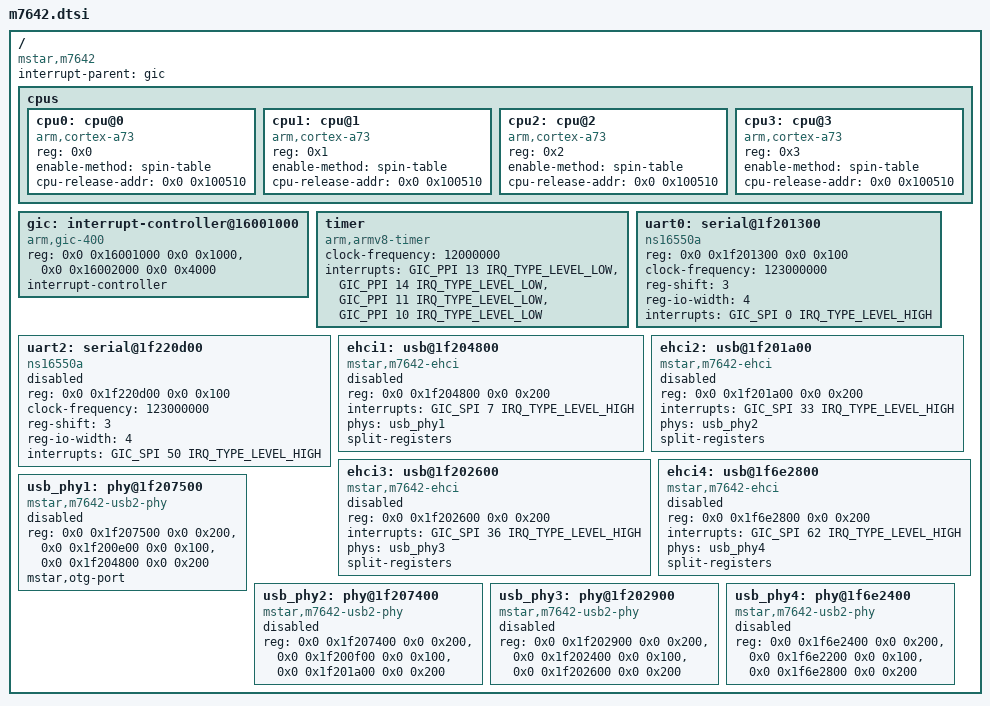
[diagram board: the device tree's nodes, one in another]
// SPDX-License-Identifier: (GPL-2.0+ OR MIT)
/*
 * MStar m7642 (marketed by MediaTek as MT9652)
 *
 * Only the blocks that mainline Linux can drive are described.  Everything
 * else on this SoC is behind closed HAL code with no documented register
 * map, so inventing nodes for it would only produce empty drivers.  See
 * Documentation/mstar/m7642/ for what is known about each block.
 *
 * Naming: the vendor DT roots at "arm,m7642"; upstream wants the real
 * vendor prefix, which is registered as "mstar," in vendor-prefixes.yaml.
 */

#include <dt-bindings/interrupt-controller/arm-gic.h>

/ {
	compatible = "mstar,m7642";
	#address-cells = <2>;
	#size-cells = <2>;
	interrupt-parent = <&gic>;

	cpus {
		#address-cells = <1>;
		#size-cells = <0>;

		cpu0: cpu@0 {
			device_type = "cpu";
			compatible = "arm,cortex-a73";
			reg = <0x0>;
			enable-method = "spin-table";
			cpu-release-addr = <0x0 0x100510>;
		};

		cpu1: cpu@1 {
			device_type = "cpu";
			compatible = "arm,cortex-a73";
			reg = <0x1>;
			enable-method = "spin-table";
			cpu-release-addr = <0x0 0x100510>;
		};

		cpu2: cpu@2 {
			device_type = "cpu";
			compatible = "arm,cortex-a73";
			reg = <0x2>;
			enable-method = "spin-table";
			cpu-release-addr = <0x0 0x100510>;
		};

		cpu3: cpu@3 {
			device_type = "cpu";
			compatible = "arm,cortex-a73";
			reg = <0x3>;
			enable-method = "spin-table";
			cpu-release-addr = <0x0 0x100510>;
		};
	};

	/*
	 * The firmware has no PSCI.  The vendor release protocol is a three
	 * word mailbox at pm_base + (cpu-release-addr * 2) followed by an ack
	 * handshake, which does not match mainline spin-table.  Booting with
	 * maxcpus=1 is the only thing that works until a matching
	 * cpu_operations implementation exists (see smp.md).
	 */

	gic: interrupt-controller@16001000 {
		compatible = "arm,gic-400";
		reg = <0x0 0x16001000 0x0 0x1000>,	/* GICD */
		      <0x0 0x16002000 0x0 0x4000>;	/* GICC */
		interrupt-controller;
		#interrupt-cells = <3>;
	};

	/*
	 * No timer node in the vendor DT -- its board code registers the
	 * architected timer by hand.  The PPI assignments below are the
	 * architectural ones and need no knowledge of the SoC.
	 *
	 * clock-frequency is 12 MHz, read out of the vendor DT (0xb71b00).
	 * It has to be spelled out: mboot does not program CNTFRQ_EL0, and
	 * without a frequency the driver cannot register a clock event and
	 * the kernel panics before it can print anything.
	 */
	timer {
		compatible = "arm,armv8-timer";
		clock-frequency = <12000000>;
		interrupts = <GIC_PPI 13 IRQ_TYPE_LEVEL_LOW>,
			     <GIC_PPI 14 IRQ_TYPE_LEVEL_LOW>,
			     <GIC_PPI 11 IRQ_TYPE_LEVEL_LOW>,
			     <GIC_PPI 10 IRQ_TYPE_LEVEL_LOW>;
	};

	/*
	 * 8250 with 8-byte register stride: register N lives at byte
	 * offset N * 8.  The vendor patch redefines the register offsets to
	 * 0x00/0x02/0x04.. and then shifts by two, which is the same thing
	 * as reg-shift = <3> with 32-bit access.  123 MHz on real silicon.
	 */
	uart0: serial@1f201300 {
		compatible = "ns16550a";
		reg = <0x0 0x1f201300 0x0 0x100>;
		clock-frequency = <123000000>;
		reg-shift = <3>;
		reg-io-width = <4>;
		interrupts = <GIC_SPI 0 IRQ_TYPE_LEVEL_HIGH>;
	};

	/*
	 * mboot prints on UART2 (its env says console=ttyS2,115200n8) while
	 * the vendor kernel uses UART0.  Enable this one as well when a serial
	 * cable is attached, otherwise the bootloader stage looks silent.
	 * Kept disabled by default: the input clock has not been measured yet.
	 */
	uart2: serial@1f220d00 {
		compatible = "ns16550a";
		reg = <0x0 0x1f220d00 0x0 0x100>;
		clock-frequency = <123000000>;
		reg-shift = <3>;
		reg-io-width = <4>;
		interrupts = <GIC_SPI 50 IRQ_TYPE_LEVEL_HIGH>;
		status = "disabled";
	};

	/*
	 * Four EHCI controllers, all with 16-bit registers (see
	 * "split-registers" below).  The addresses are the vendor "ehc" base
	 * inside the USB block at 0x1f200000, the interrupts are the vendor
	 * virqs from /proc/interrupts minus 32, and the bus number column is
	 * what the hardware reports at runtime:
	 *
	 *   ehci1  0x4800  virq 39  -> SPI  7  bus usb2
	 *   ehci2  0x1a00  virq 65  -> SPI 33  bus usb1
	 *   ehci3  0x2600  virq 68  -> SPI 36  bus usb3  (MT7663 wifi/BT)
	 *   ehci4  0x4e2800 virq 94 -> SPI 62  bus usb4
	 *
	 * Disabled on purpose: the UTMI PHY sequence is not in the kernel
	 * yet, and the port never leaves reset without it.
	 */
	ehci1: usb@1f204800 {
		compatible = "mstar,m7642-ehci", "generic-ehci";
		reg = <0x0 0x1f204800 0x0 0x200>;
		interrupts = <GIC_SPI 7 IRQ_TYPE_LEVEL_HIGH>;
		phys = <&usb_phy1>;
		split-registers;
		status = "disabled";
	};

	ehci2: usb@1f201a00 {
		compatible = "mstar,m7642-ehci", "generic-ehci";
		reg = <0x0 0x1f201a00 0x0 0x200>;
		interrupts = <GIC_SPI 33 IRQ_TYPE_LEVEL_HIGH>;
		phys = <&usb_phy2>;
		split-registers;
		status = "disabled";
	};

	ehci3: usb@1f202600 {
		compatible = "mstar,m7642-ehci", "generic-ehci";
		reg = <0x0 0x1f202600 0x0 0x200>;
		interrupts = <GIC_SPI 36 IRQ_TYPE_LEVEL_HIGH>;
		phys = <&usb_phy3>;
		split-registers;
		status = "disabled";
	};

	ehci4: usb@1f6e2800 {
		compatible = "mstar,m7642-ehci", "generic-ehci";
		reg = <0x0 0x1f6e2800 0x0 0x200>;
		interrupts = <GIC_SPI 62 IRQ_TYPE_LEVEL_HIGH>;
		phys = <&usb_phy4>;
		split-registers;
		status = "disabled";
	};

	/*
	 * One PHY per port.  The UHC window is the same register file the EHCI
	 * node maps, hence the overlap; the driver maps it without reserving.
	 * Port 1 is the OTG capable one, which is why its PHY is told to leave
	 * the UHC select bit to the device controller.
	 */
	usb_phy1: phy@1f207500 {
		compatible = "mstar,m7642-usb2-phy";
		reg = <0x0 0x1f207500 0x0 0x200>,
		      <0x0 0x1f200e00 0x0 0x100>,
		      <0x0 0x1f204800 0x0 0x200>;
		reg-names = "utmi", "usbc", "uhc";
		#phy-cells = <0>;
		mstar,otg-port;
		status = "disabled";
	};

	usb_phy2: phy@1f207400 {
		compatible = "mstar,m7642-usb2-phy";
		reg = <0x0 0x1f207400 0x0 0x200>,
		      <0x0 0x1f200f00 0x0 0x100>,
		      <0x0 0x1f201a00 0x0 0x200>;
		reg-names = "utmi", "usbc", "uhc";
		#phy-cells = <0>;
		status = "disabled";
	};

	usb_phy3: phy@1f202900 {
		compatible = "mstar,m7642-usb2-phy";
		reg = <0x0 0x1f202900 0x0 0x200>,
		      <0x0 0x1f202400 0x0 0x100>,
		      <0x0 0x1f202600 0x0 0x200>;
		reg-names = "utmi", "usbc", "uhc";
		#phy-cells = <0>;
		status = "disabled";
	};

	usb_phy4: phy@1f6e2400 {
		compatible = "mstar,m7642-usb2-phy";
		reg = <0x0 0x1f6e2400 0x0 0x200>,
		      <0x0 0x1f6e2200 0x0 0x100>,
		      <0x0 0x1f6e2800 0x0 0x200>;
		reg-names = "utmi", "usbc", "uhc";
		#phy-cells = <0>;
		status = "disabled";
	};
};
